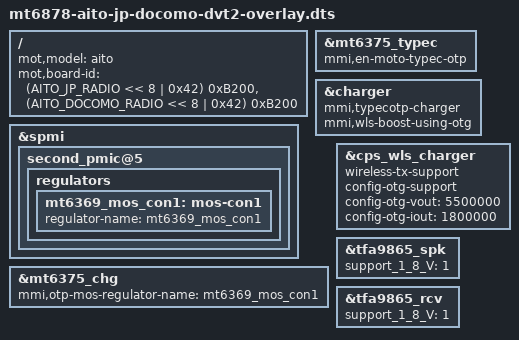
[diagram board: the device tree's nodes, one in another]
/* Copyright (c) 2023, Motorola Mobility Inc. All rights reserved.
 *
 * This program is free software; you can redistribute it and/or modify
 * it under the terms of the GNU General Public License version 2 and
 * only version 2 as published by the Free Software Foundation.
 *
 * This program is distributed in the hope that it will be useful,
 * but WITHOUT ANY WARRANTY; without even the implied warranty of
 * MERCHANTABILITY or FITNESS FOR A PARTICULAR PURPOSE.  See the
 * GNU General Public License for more details.
 */

/dts-v1/;
/plugin/;

#include "mediatek/mt6878-aito-common-overlay.dtsi"

#define AITO_JP_RADIO 4
#define AITO_DOCOMO_RADIO 5

/* Board match root node */
/ {
	fragment@model {
		target-path = "/";
		__overlay__ {
			mot,model = "aito";
			mot,board-id = <(AITO_JP_RADIO << 8 | 0x42) 0xB200>, <(AITO_DOCOMO_RADIO << 8 | 0x42) 0xB200>;
		};
	};
};

&mt6375_typec {
	mmi,en-moto-typec-otp;
};

&charger {
	/*typec_otp*/
	mmi,typecotp-charger;
	mmi,wls-boost-using-otg;
};

&spmi {
	second_pmic@5 {
		regulators {
			mt6369_mos_con1: mos-con1 {
				regulator-name = "mt6369_mos_con1";
			};
		};
	};
};

&mt6375_chg {
	mmi,otp-mos-regulator-name = "mt6369_mos_con1";
};

&cps_wls_charger {
	wireless-tx-support;
	config-otg-support;
	config-otg-vout = <5500000>;
	config-otg-iout = <1800000>;
};

&tfa9865_spk {
    support_1_8_V=<1>;
};

&tfa9865_rcv {
    support_1_8_V=<1>;
};

#include <aito_dvt2/cust.dtsi>
/*End of this file, DO NOT ADD ANYTHING HERE*/
